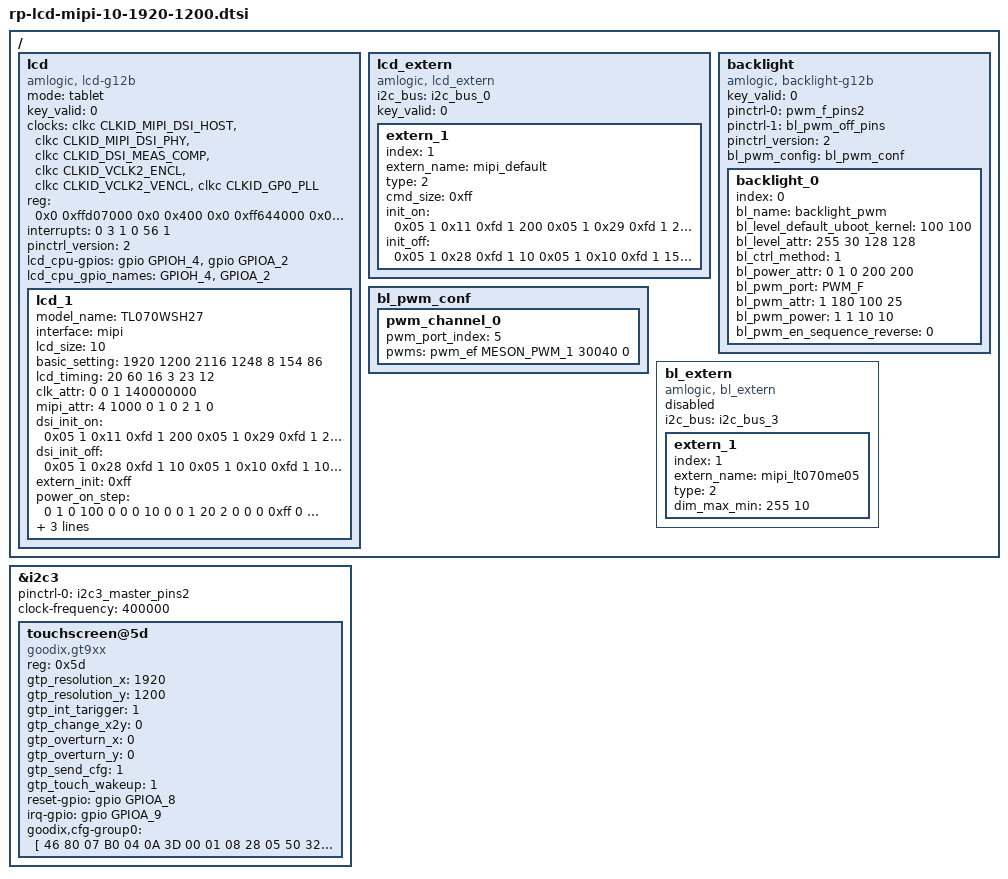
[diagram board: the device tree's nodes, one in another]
/*
 * arch/arm64/boot/dts/amlogic/mesong12b_skt-panel.dtsi
 *
 * Copyright (C) 2016 Amlogic, Inc. All rights reserved.
 *
 * This program is free software; you can redistribute it and/or modify
 * it under the terms of the GNU General Public License as published by
 * the Free Software Foundation; either version 2 of the License, or
 * (at your option) any later version.
 *
 * This program is distributed in the hope that it will be useful, but WITHOUT
 * ANY WARRANTY; without even the implied warranty of MERCHANTABILITY or
 * FITNESS FOR A PARTICULAR PURPOSE.  See the GNU General Public License for
 * more details.
 *
 */

/ {
	lcd{
		compatible = "amlogic, lcd-g12b";
		mode = "tablet";
		status = "okay";
		key_valid = <0>;
		clocks = <&clkc CLKID_MIPI_DSI_HOST
			&clkc CLKID_MIPI_DSI_PHY
			&clkc CLKID_DSI_MEAS_COMP
			&clkc CLKID_VCLK2_ENCL
			&clkc CLKID_VCLK2_VENCL
			&clkc CLKID_GP0_PLL>;
		clock-names = "dsi_host_gate",
			"dsi_phy_gate",
			"dsi_meas",
			"encl_top_gate",
			"encl_int_gate",
			"gp0_pll";
		reg = <0x0 0xffd07000 0x0 0x400    /* dsi_host */
			0x0 0xff644000 0x0 0x200>; /* dsi_phy */
		interrupts = <0 3 1
			0 56 1>;
		interrupt-names = "vsync","vsync2";
		pinctrl_version = <2>; /* for uboot */

		/* power type:
		 *    (0=cpu_gpio, 1=pmu_gpio, 2=signal,3=extern, 0xff=ending)
		 * power index:
		 *    (point gpios_index, or extern_index,0xff=invalid)
		 * power value:(0=output low, 1=output high, 2=input)
		 * power delay:(unit in ms)
		 */
		lcd_cpu-gpios = <&gpio GPIOH_4 GPIO_ACTIVE_HIGH
				&gpio GPIOA_2 GPIO_ACTIVE_HIGH>;
		lcd_cpu_gpio_names = "GPIOH_4","GPIOA_2";


		lcd_1{
			model_name = "TL070WSH27";
			interface = "mipi";
			lcd_size = "10";
			basic_setting = <1920 1200 /*h_active, v_active*/
				2116 1248 /*h_period, v_period*/
				8 /*lcd_bits*/
				154 86>; /*screen_widht, screen_height*/
			lcd_timing = <20 60 16 /*hs_width, hs_bp, hs_pol*/
				3 23 12>; /*vs_width, vs_bp, vs_pol*/
			clk_attr = <0 /*fr_adj_type(0=clk, 1=htotal, 2=vtotal)*/
				0 /*clk_ss_level */
				1 /*clk_auto_generate*/
				140000000>; /*pixel_clk(unit in Hz)*/
			mipi_attr = <4 /*lane_num*/
				1000 /*bit_rate_max(MHz)*/
				0 /*factor(*100, default 0 for auto)*/
				1 /*operation_mode_init(0=video, 1=command)*/
				0 /*operation_mode_display(0=video, 1=command)*/
				2 /*
				   *video_mode_type
				   *(0=sync_pulse,1=sync_event,2=burst)
				   */
				1 /*clk_always_hs(0=disable,1=enable)*/
				0>; /*phy_switch(0=auto,1=standard,2=slow)*/

			/* dsi_init: data_type, num, data... */
			dsi_init_on = <0x05 1 0x11
					0xfd 1 200  /*delay(ms)*/
					0x05 1 0x29
					0xfd 1 20   /*delay(ms)*/
					0xff 0>;    /*ending*/
			dsi_init_off = <0x05 1 0x28
					0xfd 1 10   /*delay(ms)*/
					0x05 1 0x10
					0xfd 1 10   /*delay(ms)*/
					0xff 0>;    /*ending*/
			extern_init = <0xff>; /*0xff for invalid*/

			/* power step: type, index, value, delay(ms) */
			power_on_step = <
				0 1 0 100
				0 0 0 10
				0 0 1 20
				2 0 0 0
				0xff 0 0 0>; /*ending*/
			power_off_step = <
				2 0 0 50
				0 0 0 10
				0 1 1 100
				0xff 0 0 0>; /*ending*/
			backlight_index = <0>;
		};
	};

	lcd_extern{
		compatible = "amlogic, lcd_extern";
		status = "okay";
		i2c_bus = "i2c_bus_0";
		key_valid = <0>;

		extern_1{
			index = <1>;
			extern_name = "mipi_default";/*P070ACB_FT*/
			status = "okay";
			type = <2>; /* 0=i2c, 1=spi, 2=mipi */
			cmd_size = <0xff>;
			init_on = <
				0x05 1 0x11  /* display on */
				0xfd 1 200

				0x05 1 0x29 /* display on */
				0xfd 1 200
				0xFF 0>; /*ending*/
			init_off = <
				0x05 1 0x28 /* display off */
				0xfd 1 10   /* delay 10ms */
				0x05 1 0x10 /* sleep in */
				0xfd 1 150  /* delay 150ms */
				0xff 0>;    /*ending*/
		};
	};

	backlight{
		compatible = "amlogic, backlight-g12b";
		status = "okay";
		key_valid = <0>;
		pinctrl-names = "pwm_on","pwm_off";
		pinctrl-0 = <&pwm_f_pins2>;
		pinctrl-1 = <&bl_pwm_off_pins>;
		pinctrl_version = <2>; /* for uboot */
		bl_pwm_config = <&bl_pwm_conf>;
		//bl-gpios = <&gpio GPIOH_4 GPIO_ACTIVE_HIGH
		//	&gpio GPIOH_5 GPIO_ACTIVE_HIGH>;
		//bl_gpio_names = "GPIOH_4","GPIOH_5";

		/* pwm port: PWM_A, PWM_B, PWM_C, PWM_D, PWM_E, PWM_F, PWM_VS*/
		/* power index:(point gpios_index, 0xff=invalid)
		 * power value:(0=output low, 1=output high, 2=input)
		 * power delay:(unit in ms)
		 */

		backlight_0{
			index = <0>;
			bl_name = "backlight_pwm";
			bl_level_default_uboot_kernel = <100 100>;
			bl_level_attr = <255 30 /*max, min*/
				128 128>; /*mid, mid_mapping*/
			bl_ctrl_method = <1>; /* 1=pwm, 2=pwm_combo, 4=extern */
			bl_power_attr = <0 /*en_gpio_index*/
				1 0 /*on_value, off_value*/
				200 200>; /*on_delay(ms), off_delay(ms)*/
			bl_pwm_port = "PWM_F";
			bl_pwm_attr = <1 /*pwm_method*/
				180 /*pwm_freq(pwm:Hz, pwm_vs:multiple of vs)*/
				100 25>; /*duty_max(%), duty_min(%)*/
			bl_pwm_power = <1 1 /*pwm_gpio_index, pwm_gpio_off*/
				10 10>; /*pwm_on_delay(ms), pwm_off_delay(ms)*/
			bl_pwm_en_sequence_reverse = <0>; /* 1 for reverse */
		};
	};
	bl_pwm_conf:bl_pwm_conf{
		pwm_channel_0 {
			pwm_port_index = <5>;
			pwms = <&pwm_ef MESON_PWM_1 30040 0>;
		};
	};

	bl_extern{
		compatible = "amlogic, bl_extern";
		status = "disabled";
		i2c_bus = "i2c_bus_3";

		extern_1{
			index = <1>;
			extern_name = "mipi_lt070me05";
			type = <2>; /*0=i2c, 1=spi, 2=mipi*/
			dim_max_min = <255 10>;
		};
	};
};/* end of panel */


&i2c3 {
        status = "okay";
        pinctrl-names = "default";
        pinctrl-0 = <&i2c3_master_pins2>;
        clock-frequency = <400000>;

        touchscreen@5d {
                compatible = "goodix,gt9xx";
                status = "okay";
                reg = <0x5d>;
		gtp_resolution_x = <1920>;
		gtp_resolution_y = <1200>;
		gtp_int_tarigger = <1>;
		gtp_change_x2y = <0>;
		gtp_overturn_x = <0>;
		gtp_overturn_y = <0>;
		gtp_send_cfg = <1>;
		gtp_touch_wakeup = <1>;
                reset-gpio = <&gpio GPIOA_8 GPIO_ACTIVE_HIGH>;
                irq-gpio = <&gpio GPIOA_9 GPIO_ACTIVE_HIGH>;
                goodix,cfg-group0 = [
			46 80 07 B0 04 0A 3D 00 01 08 28
			05 50 32 03 05 00 00 00 00 00 00
			00 18 1A 1E 14 8E 2F 99 17 15 31
			0D 00 00 02 9B 03 1D 00 00 00 00
			00 00 00 00 00 00 00 1E 78 94 C5
			02 08 00 00 00 5B 22 00 4C 2D 00
			41 3C 00 38 4F 00 32 69 00 32 00
			00 00 00 00 00 00 00 00 00 00 00
			00 00 00 00 00 00 00 00 00 00 00
			00 00 00 00 00 00 00 00 00 00 00
			00 00 00 01 04 05 06 07 08 09 0C
			0D 0E 0F 10 11 14 15 16 17 FF FF
			00 00 00 00 00 00 00 00 00 00 00
			02 04 06 07 08 0A 0C 0D 0F 10 11
			12 13 19 1B 1C 1E 1F 20 21 22 23
			24 25 26 27 28 29 FF FF FF 00 00
			00 00 00 00 00 00 00 00 6B 01
			];
        };
};
